# ATSAMC21J18A register map
Vendor: Microchip Technology; Series: SAMC21; File version: 0
CPU: CM0+ r0p0, selectable endian, MPU, no FPU, VTOR, 2 interrupt priority bits
Registers are 32-bit, read-write, reset 0x0 unless marked. A register's access mark holds for its fields unless they carry their own. Offsets are from the block's base; [hi:lo] are bit positions; 'fields as' and 'values as' point back to an identical list.

## PTC — Peripheral Touch Controller
Base 0x42005800; register names take the prefix PTC_

## RSTC — Reset Controller
Base 0x40000C00; register names take the prefix RSTC_
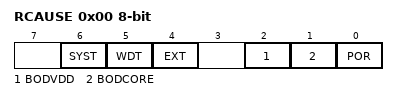
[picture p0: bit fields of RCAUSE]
0x00 RCAUSE 8-bit ro — Reset Cause
  [6] SYST — System Reset Request
  [5] WDT — Watchdog Reset
  [4] EXT — External Reset
  [2] BODVDD — Brown Out VDD Detector Reset
  [1] BODCORE — Brown Out CORE Detector Reset
  [0] POR — Power On Reset

## SUPC — Supply Controller
Base 0x40001800; register names take the prefix SUPC_
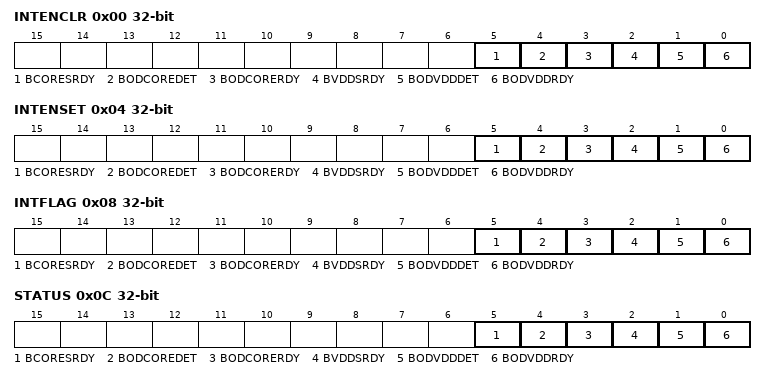
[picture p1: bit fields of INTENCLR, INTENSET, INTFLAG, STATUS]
0x00 INTENCLR — Interrupt Enable Clear
  [5] BCORESRDY — BODCORE Synchronization Ready
  [4] BODCOREDET — BODCORE Detection
  [3] BODCORERDY — BODCORE Ready
  [2] BVDDSRDY — BODVDD Synchronization Ready
  [1] BODVDDDET — BODVDD Detection
  [0] BODVDDRDY — BODVDD Ready
0x04 INTENSET — Interrupt Enable Set
  fields as INTENCLR
0x08 INTFLAG — Interrupt Flag Status and Clear
  fields as INTENCLR
0x0C STATUS ro — Power and Clocks Status
  fields as INTENCLR
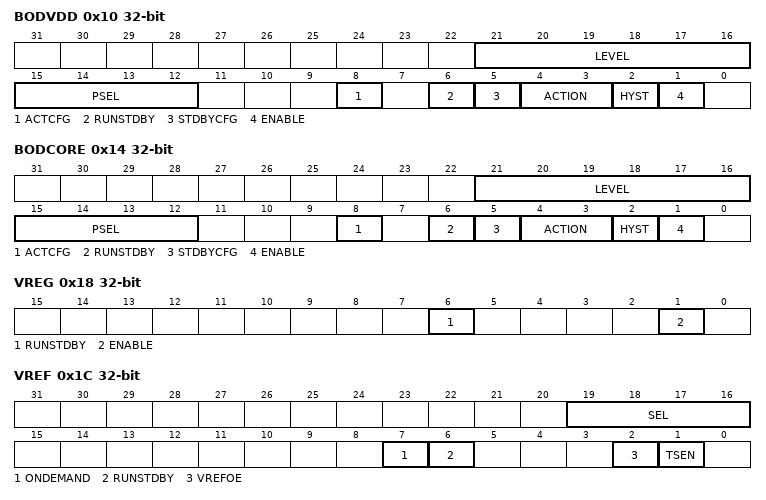
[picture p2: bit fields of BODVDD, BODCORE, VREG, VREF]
0x10 BODVDD — BODVDD Control
  [21:16] LEVEL — Threshold Level for VDD
  [15:12] PSEL — Prescaler Select
    0=DIV2 (Divide clock by 2); 1=DIV4 (Divide clock by 4); 2=DIV8 (Divide clock by 8); 3=DIV16 (Divide clock by 16); 4=DIV32 (Divide clock by 32); 5=DIV64 (Divide clock by 64); 6=DIV128 (Divide clock by 128); 7=DIV256 (Divide clock by 256); 8=DIV512 (Divide clock by 512); 9=DIV1024 (Divide clock by 1024); 10=DIV2048 (Divide clock by 2048); 11=DIV4096 (Divide clock by 4096); 12=DIV8192 (Divide clock by 8192); 13=DIV16384 (Divide clock by 16384); 14=DIV32768 (Divide clock by 32768); 15=DIV65536 (Divide clock by 65536)
  [8] ACTCFG — Configuration in Active mode
  [6] RUNSTDBY — Run during Standby
  [5] STDBYCFG — Configuration in Standby mode
  [4:3] ACTION — Action when Threshold Crossed
    0=NONE (No action); 1=RESET (The BODVDD generates a reset); 2=INT (The BODVDD generates an interrupt)
  [2] HYST — Hysteresis Enable
  [1] ENABLE
0x14 BODCORE — BODCORE Control
  [21:16] LEVEL — Threshold Level
  [15:12] PSEL — Prescaler Select
    values as BODVDD.PSEL
  [8] ACTCFG — Configuration in Active mode
  [6] RUNSTDBY — Run during Standby
  [5] STDBYCFG — Configuration in Standby mode
  [4:3] ACTION — Action when Threshold Crossed
    0=NONE (No action); 1=RESET (The BODCORE generates a reset); 2=INT (The BODCORE generates an interrupt)
  [2] HYST — Hysteresis Enable
  [1] ENABLE
0x18 VREG — VREG Control
  [6] RUNSTDBY — Run during Standby
  [1] ENABLE
0x1C VREF — VREF Control
  [19:16] SEL — Voltage Reference Selection
    0=1V024 (1.024V voltage reference typical value); 2=2V048 (2.048V voltage reference typical value); 3=4V096 (4.096V voltage reference typical value)
  [7] ONDEMAND — On Demand Contrl
  [6] RUNSTDBY — Run during Standby
  [2] VREFOE — Voltage Reference Output Enable
  [1] TSEN — Temperature Sensor Output Enable

## TSENS — Temperature Sensor
Base 0x40003000; register names take the prefix TSENS_
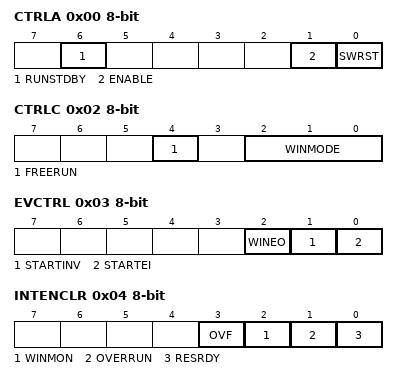
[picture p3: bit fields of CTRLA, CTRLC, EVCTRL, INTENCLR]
0x00 CTRLA 8-bit — Control A Register
  [6] RUNSTDBY — Run in Standby
  [1] ENABLE
  [0] SWRST — Software Reset
0x01 CTRLB 8-bit wo — Control B Register
  [0] START — Start Measurement
0x02 CTRLC 8-bit — Control C Register
  [4] FREERUN — Free Running Measurement
  [2:0] WINMODE — Window Monitor Mode
    0=DISABLE (No window mode (default)); 1=ABOVE (VALUE greater than WINLT); 2=BELOW (VALUE less than WINUT); 3=INSIDE (VALUE greater than WINLT and VALUE less than WINUT); 4=OUTSIDE (VALUE less than WINLT or VALUE greater than WINUT); 5=HYST_ABOVE (VALUE greater than WINUT with hysteresis to WINLT); 6=HYST_BELOW (VALUE less than WINLST with hysteresis to WINUT)
0x03 EVCTRL 8-bit — Event Control Register
  [2] WINEO — Window Monitor Event Out
  [1] STARTINV — Start Conversion Event Invert Enable
  [0] STARTEI — Start Conversion Event Input Enable
0x04 INTENCLR 8-bit — Interrupt Enable Clear Register
  [3] OVF — Overflow Interrupt Enable
  [2] WINMON — Window Monitor Interrupt Enable
  [1] OVERRUN — Overrun Interrupt Enable
  [0] RESRDY — Result Ready Interrupt Enable
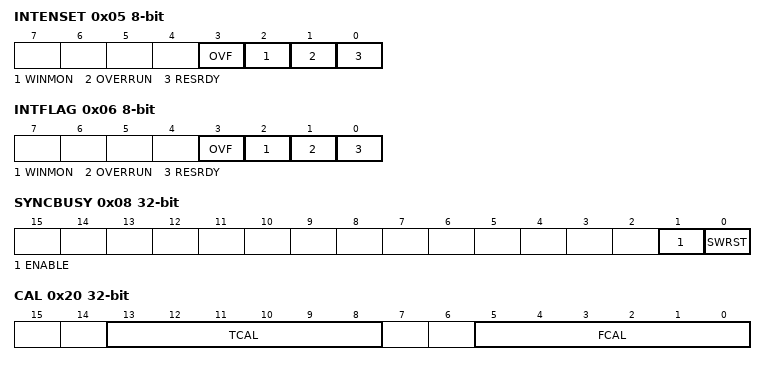
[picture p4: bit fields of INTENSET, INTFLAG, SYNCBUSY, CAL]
0x05 INTENSET 8-bit — Interrupt Enable Set Register
  fields as INTENCLR
0x06 INTFLAG 8-bit — Interrupt Flag Status and Clear Register
  [3] OVF — Overflow
  [2] WINMON — Window Monitor
  [1] OVERRUN
  [0] RESRDY — Result Ready
0x07 STATUS 8-bit ro
  [0] OVF — Result Overflow
0x08 SYNCBUSY ro — Synchronization Busy Register
  [1] ENABLE — Enable Busy
  [0] SWRST — Software Reset Busy
0x0C VALUE ro
  [23:0] VALUE — Measurement Value
0x10 WINLT — Window Monitor Lower Threshold Register
  [23:0] WINLT — Window Lower Threshold
0x14 WINUT — Window Monitor Upper Threshold Register
  [23:0] WINUT — Window Upper Threshold
0x18 GAIN
  [23:0] GAIN — Time Amplifier Gain
0x1C OFFSET
  [23:0] OFFSETC — Offset Correction
0x20 CAL — Calibration Register
  [13:8] TCAL — Temperature Calibration
  [5:0] FCAL — Frequency Calibration
0x24 DBGCTRL 8-bit — Debug Control Register
  [0] DBGRUN — Debug Run

## Notices in the file
Copyright (c) 2017 Microchip Technology Inc.
SPDX-License-Identifier: Apache-2.0
Licensed under the Apache License, Version 2.0 (the "License");
you may not use this file except in compliance with the License.
You may obtain a copy of the License at
http://www.apache.org/licenses/LICENSE-2.0
Unless required by applicable law or agreed to in writing, software
distributed under the License is distributed on an "AS IS" BASIS,
WITHOUT WARRANTIES OR CONDITIONS OF ANY KIND, either express or implied.
See the License for the specific language governing permissions and
limitations under the License.
